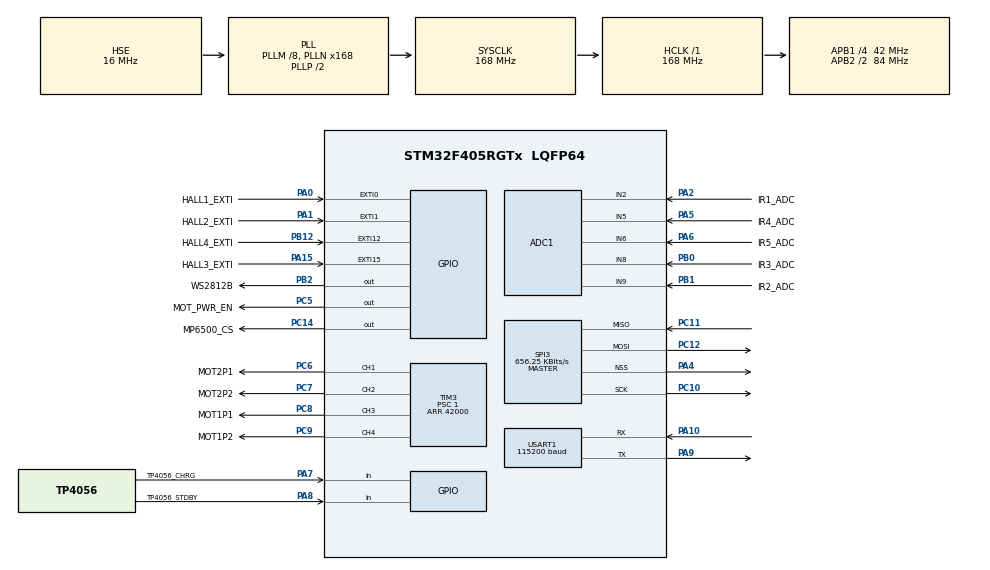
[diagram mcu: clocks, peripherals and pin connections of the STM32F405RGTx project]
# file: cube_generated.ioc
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ADC1.Channel-0\#ChannelRegularConversion=ADC_CHANNEL_2
ADC1.Channel-1\#ChannelRegularConversion=ADC_CHANNEL_5
ADC1.Channel-2\#ChannelRegularConversion=ADC_CHANNEL_6
ADC1.Channel-3\#ChannelRegularConversion=ADC_CHANNEL_8
ADC1.Channel-4\#ChannelRegularConversion=ADC_CHANNEL_9
ADC1.ClockPrescaler=ADC_CLOCK_SYNC_PCLK_DIV8
ADC1.ContinuousConvMode=DISABLE
ADC1.DMAContinuousRequests=ENABLE
ADC1.EOCSelection=ADC_EOC_SEQ_CONV
ADC1.ExternalTrigConv=ADC_EXTERNALTRIGCONV_T8_TRGO
ADC1.InjNumberOfConversion=0
ADC1.NbrOfConversion=5
ADC1.NbrOfConversionFlag=1
ADC1.Rank-0\#ChannelRegularConversion=1
ADC1.Rank-1\#ChannelRegularConversion=2
ADC1.Rank-2\#ChannelRegularConversion=3
ADC1.Rank-3\#ChannelRegularConversion=4
ADC1.Rank-4\#ChannelRegularConversion=5
ADC1.SamplingTime-0\#ChannelRegularConversion=ADC_SAMPLETIME_480CYCLES
ADC1.SamplingTime-1\#ChannelRegularConversion=ADC_SAMPLETIME_480CYCLES
ADC1.SamplingTime-2\#ChannelRegularConversion=ADC_SAMPLETIME_480CYCLES
ADC1.SamplingTime-3\#ChannelRegularConversion=ADC_SAMPLETIME_480CYCLES
ADC1.SamplingTime-4\#ChannelRegularConversion=ADC_SAMPLETIME_480CYCLES
ADC1.master=1
Dma.ADC1.4.Direction=DMA_PERIPH_TO_MEMORY
Dma.ADC1.4.FIFOMode=DMA_FIFOMODE_DISABLE
Dma.ADC1.4.Instance=DMA2_Stream0
Dma.ADC1.4.MemDataAlignment=DMA_MDATAALIGN_HALFWORD
Dma.ADC1.4.MemInc=DMA_MINC_ENABLE
Dma.ADC1.4.Mode=DMA_CIRCULAR
Dma.ADC1.4.PeriphDataAlignment=DMA_PDATAALIGN_HALFWORD
Dma.ADC1.4.PeriphInc=DMA_PINC_DISABLE
Dma.ADC1.4.Priority=DMA_PRIORITY_LOW
Dma.Request0=USART1_TX
Dma.Request1=USART1_RX
Dma.Request2=SPI3_RX
Dma.Request3=SPI3_TX
Dma.Request4=ADC1
Dma.SPI3_RX.2.Direction=DMA_PERIPH_TO_MEMORY
Dma.SPI3_RX.2.FIFOMode=DMA_FIFOMODE_DISABLE
Dma.SPI3_RX.2.Instance=DMA1_Stream0
Dma.SPI3_RX.2.MemDataAlignment=DMA_MDATAALIGN_BYTE
Dma.SPI3_RX.2.MemInc=DMA_MINC_ENABLE
Dma.SPI3_RX.2.Mode=DMA_NORMAL
Dma.SPI3_RX.2.PeriphDataAlignment=DMA_PDATAALIGN_BYTE
Dma.SPI3_RX.2.PeriphInc=DMA_PINC_DISABLE
Dma.SPI3_RX.2.Priority=DMA_PRIORITY_LOW
Dma.SPI3_TX.3.Direction=DMA_MEMORY_TO_PERIPH
Dma.SPI3_TX.3.FIFOMode=DMA_FIFOMODE_DISABLE
Dma.SPI3_TX.3.Instance=DMA1_Stream5
Dma.SPI3_TX.3.MemDataAlignment=DMA_MDATAALIGN_BYTE
Dma.SPI3_TX.3.MemInc=DMA_MINC_ENABLE
Dma.SPI3_TX.3.Mode=DMA_NORMAL
Dma.SPI3_TX.3.PeriphDataAlignment=DMA_PDATAALIGN_BYTE
Dma.SPI3_TX.3.PeriphInc=DMA_PINC_DISABLE
Dma.SPI3_TX.3.Priority=DMA_PRIORITY_LOW
Dma.USART1_RX.1.Direction=DMA_PERIPH_TO_MEMORY
Dma.USART1_RX.1.FIFOMode=DMA_FIFOMODE_DISABLE
Dma.USART1_RX.1.Instance=DMA2_Stream2
Dma.USART1_RX.1.MemDataAlignment=DMA_MDATAALIGN_BYTE
Dma.USART1_RX.1.MemInc=DMA_MINC_ENABLE
Dma.USART1_RX.1.Mode=DMA_NORMAL
Dma.USART1_RX.1.PeriphDataAlignment=DMA_PDATAALIGN_BYTE
Dma.USART1_RX.1.PeriphInc=DMA_PINC_DISABLE
Dma.USART1_RX.1.Priority=DMA_PRIORITY_LOW
Dma.USART1_TX.0.Direction=DMA_MEMORY_TO_PERIPH
Dma.USART1_TX.0.FIFOMode=DMA_FIFOMODE_DISABLE
Dma.USART1_TX.0.Instance=DMA2_Stream7
Dma.USART1_TX.0.MemDataAlignment=DMA_MDATAALIGN_BYTE
Dma.USART1_TX.0.MemInc=DMA_MINC_ENABLE
Dma.USART1_TX.0.Mode=DMA_NORMAL
Dma.USART1_TX.0.PeriphDataAlignment=DMA_PDATAALIGN_BYTE
Dma.USART1_TX.0.PeriphInc=DMA_PINC_DISABLE
Dma.USART1_TX.0.Priority=DMA_PRIORITY_LOW
Mcu.Family=STM32F4
Mcu.Name=STM32F405RGTx
Mcu.Package=LQFP64
NVIC.DMA1_Stream0_IRQn=true\:12\:0\:true\:false\:true\:false\:true\:true
NVIC.DMA1_Stream5_IRQn=true\:12\:0\:true\:false\:true\:false\:true\:true
NVIC.DMA2_Stream0_IRQn=true\:9\:0\:true\:false\:true\:false\:true\:true
NVIC.DMA2_Stream2_IRQn=true\:13\:0\:true\:false\:true\:false\:true\:true
NVIC.DMA2_Stream7_IRQn=true\:13\:0\:true\:false\:true\:false\:true\:true
NVIC.EXTI0_IRQn=true\:5\:0\:true\:false\:true\:true\:true\:true
NVIC.EXTI15_10_IRQn=true\:5\:0\:true\:false\:true\:true\:true\:true
NVIC.EXTI1_IRQn=true\:5\:0\:true\:false\:true\:true\:true\:true
NVIC.PriorityGroup=NVIC_PRIORITYGROUP_4
NVIC.TIM1_UP_TIM10_IRQn=true\:0\:0\:false\:false\:false\:true\:true\:true
NVIC.TIM2_IRQn=true\:0\:0\:false\:false\:true\:true\:true\:true
NVIC.TIM6_DAC_IRQn=true\:15\:0\:false\:false\:true\:false\:true\:true
NVIC.TIM8_TRG_COM_TIM14_IRQn=true\:5\:0\:true\:false\:true\:true\:true\:true
NVIC.TIM8_UP_TIM13_IRQn=true\:5\:0\:true\:false\:true\:true\:true\:true
NVIC.TimeBase=TIM6_DAC_IRQn
NVIC.TimeBaseIP=TIM6
NVIC.USART1_IRQn=true\:13\:0\:true\:false\:true\:true\:true\:true
PA0-WKUP.GPIO_Label=HALL1_EXTI
PA0-WKUP.GPIO_ModeDefaultEXTI=GPIO_MODE_IT_RISING_FALLING
PA0-WKUP.Signal=GPXTI0
PA1.GPIO_Label=HALL2_EXTI
PA1.GPIO_ModeDefaultEXTI=GPIO_MODE_IT_RISING_FALLING
PA1.Signal=GPXTI1
PA10.Mode=Asynchronous
PA10.Signal=USART1_RX
PA13.Mode=Trace_Asynchronous_SW
PA13.Signal=SYS_JTMS-SWDIO
PA14.Mode=Trace_Asynchronous_SW
PA14.Signal=SYS_JTCK-SWCLK
PA15.GPIO_Label=HALL3_EXTI
PA15.GPIO_ModeDefaultEXTI=GPIO_MODE_IT_RISING_FALLING
PA15.Signal=GPXTI15
PA2.GPIO_Label=IR1_ADC
PA2.Signal=ADCx_IN2
PA4.Mode=NSS_Signal_Hard_Output
PA4.Signal=SPI3_NSS
PA5.GPIO_Label=IR4_ADC
PA5.Signal=ADCx_IN5
PA6.GPIO_Label=IR5_ADC
PA6.Signal=ADCx_IN6
PA7.GPIO_Label=TP4056_CHRG
PA7.Signal=GPIO_Input
PA8.GPIO_Label=TP4056_STDBY
PA8.Signal=GPIO_Input
PA9.Mode=Asynchronous
PA9.Signal=USART1_TX
PB0.GPIO_Label=IR3_ADC
PB0.Signal=ADCx_IN8
PB1.GPIO_Label=IR2_ADC
PB1.Signal=ADCx_IN9
PB12.GPIO_Label=HALL4_EXTI
PB12.GPIO_ModeDefaultEXTI=GPIO_MODE_IT_RISING_FALLING
PB12.GPIO_PuPd=GPIO_PULLUP
PB12.Signal=GPXTI12
PB2.GPIO_Label=WS2812B
PB2.Signal=GPIO_Output
PB3.Mode=Trace_Asynchronous_SW
PB3.Signal=SYS_JTDO-SWO
PB8.Signal=S_TIM10_CH1
PC10.Mode=Full_Duplex_Master
PC10.Signal=SPI3_SCK
PC11.Mode=Full_Duplex_Master
PC11.Signal=SPI3_MISO
PC12.Mode=Full_Duplex_Master
PC12.Signal=SPI3_MOSI
PC14-OSC32_IN.GPIO_Label=MP6500_CS
PC14-OSC32_IN.Signal=GPIO_Output
PC5.GPIO_Label=MOT_PWR_EN
PC5.Signal=GPIO_Output
PC6.GPIO_Label=MOT2P1
PC6.Signal=S_TIM3_CH1
PC7.GPIO_Label=MOT2P2
PC7.Signal=S_TIM3_CH2
PC8.GPIO_Label=MOT1P1
PC8.Signal=S_TIM3_CH3
PC9.GPIO_Label=MOT1P2
PC9.Signal=S_TIM3_CH4
PH0-OSC_IN.Mode=HSE-External-Oscillator
PH0-OSC_IN.Signal=RCC_OSC_IN
PH1-OSC_OUT.Mode=HSE-External-Oscillator
PH1-OSC_OUT.Signal=RCC_OSC_OUT
ProjectManager.HeapSize=0x800
ProjectManager.StackSize=0x800
ProjectManager.TargetToolchain=Makefile
RCC.48MHZClocksFreq_Value=84000000
RCC.AHBFreq_Value=168000000
RCC.APB1CLKDivider=RCC_HCLK_DIV4
RCC.APB1Freq_Value=42000000
RCC.APB1TimFreq_Value=84000000
RCC.APB2CLKDivider=RCC_HCLK_DIV2
RCC.APB2Freq_Value=84000000
RCC.APB2TimFreq_Value=168000000
RCC.CortexFreq_Value=168000000
RCC.HCLKFreq_Value=168000000
RCC.HSE_VALUE=16000000
RCC.HSI_VALUE=16000000
RCC.LSE_VALUE=32768
RCC.PLLM=8
RCC.PLLN=168
RCC.PLLSourceVirtual=RCC_PLLSOURCE_HSE
RCC.SYSCLKFreq_VALUE=168000000
RCC.SYSCLKSource=RCC_SYSCLKSOURCE_PLLCLK
RCC.VCOOutputFreq_Value=336000000
SH.ADCx_IN2.0=ADC1_IN2,IN2
SH.ADCx_IN5.0=ADC1_IN5,IN5
SH.ADCx_IN6.0=ADC1_IN6,IN6
SH.ADCx_IN8.0=ADC1_IN8,IN8
SH.ADCx_IN9.0=ADC1_IN9,IN9
SH.S_TIM10_CH1.0=TIM10_CH1
SH.S_TIM3_CH1.0=TIM3_CH1,PWM Generation1 CH1
SH.S_TIM3_CH2.0=TIM3_CH2,PWM Generation2 CH2
SH.S_TIM3_CH3.0=TIM3_CH3,PWM Generation3 CH3
SH.S_TIM3_CH4.0=TIM3_CH4,PWM Generation4 CH4
SPI3.BaudRatePrescaler=SPI_BAUDRATEPRESCALER_64
SPI3.CalculateBaudRate=656.25 KBits/s
SPI3.Direction=SPI_DIRECTION_2LINES
SPI3.Mode=SPI_MODE_MASTER
SPI3.VirtualNSS=VM_NSSHARD
SPI3.VirtualType=VM_MASTER
TIM10.Channel=TIM_CHANNEL_1
TIM10.OCFastMode_PWM=TIM_OCFAST_ENABLE
TIM10.Period=104
TIM10.Prescaler=0
TIM10.Pulse=66
TIM2.Prescaler=83
TIM3.Channel-PWM\ Generation1\ CH1=TIM_CHANNEL_1
TIM3.Channel-PWM\ Generation2\ CH2=TIM_CHANNEL_2
TIM3.Channel-PWM\ Generation3\ CH3=TIM_CHANNEL_3
TIM3.Channel-PWM\ Generation4\ CH4=TIM_CHANNEL_4
TIM3.CounterMode=TIM_COUNTERMODE_CENTERALIGNED1
TIM3.Period=42000
TIM3.Prescaler=1
TIM3.Pulse-PWM\ Generation1\ CH1=40000
TIM3.Pulse-PWM\ Generation2\ CH2=2000
TIM3.Pulse-PWM\ Generation3\ CH3=10000
TIM3.Pulse-PWM\ Generation4\ CH4=30000
TIM8.AutoReloadPreload=TIM_AUTORELOAD_PRELOAD_ENABLE
TIM8.Period=999
TIM8.Prescaler=167
TIM8.TIM_MasterOutputTrigger=TIM_TRGO_UPDATE
USART1.BaudRate=115200
USART1.VirtualMode=VM_ASYNC
VP_SYS_VS_tim6.Mode=TIM6
VP_TIM10_VS_ClockSourceINT.Mode=Enable_Timer
VP_TIM10_VS_no_output1.Mode=PWM Generation1 No Output
VP_TIM2_VS_ClockSourceINT.Mode=Internal
VP_TIM3_VS_ClockSourceINT.Mode=Internal
VP_TIM8_VS_ClockSourceINT.Mode=Internal
board=custom

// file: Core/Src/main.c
/* USER CODE BEGIN Header */
/**
  ******************************************************************************
  * @file           : main.c
  * @brief          : Main program body
  ******************************************************************************
  * @attention
  *
  * Copyright (c) 2024 STMicroelectronics.
  * All rights reserved.
  *
  * This software is licensed under terms that can be found in the LICENSE file
  * in the root directory of this software component.
  * If no LICENSE file comes with this software, it is provided AS-IS.
  *
  ******************************************************************************
  */
/* USER CODE END Header */
#include "main.h"

/* USER CODE BEGIN Includes */
#include "system.h"
/* USER CODE END Includes */

ADC_HandleTypeDef hadc1;
DMA_HandleTypeDef hdma_adc1;

SPI_HandleTypeDef hspi3;
DMA_HandleTypeDef hdma_spi3_rx;
DMA_HandleTypeDef hdma_spi3_tx;

TIM_HandleTypeDef htim2;
TIM_HandleTypeDef htim3;
TIM_HandleTypeDef htim8;
TIM_HandleTypeDef htim10;

UART_HandleTypeDef huart1;
DMA_HandleTypeDef hdma_usart1_tx;
DMA_HandleTypeDef hdma_usart1_rx;

void SystemClock_Config(void);
static void MX_GPIO_Init(void);
static void MX_DMA_Init(void);
static void MX_USART1_UART_Init(void);
static void MX_ADC1_Init(void);
static void MX_SPI3_Init(void);
static void MX_TIM3_Init(void);
static void MX_TIM8_Init(void);
static void MX_TIM10_Init(void);
static void MX_TIM2_Init(void);

int main(void)
{

  /* MCU Configuration--------------------------------------------------------*/

  /* Reset of all peripherals, Initializes the Flash interface and the Systick. */
  HAL_Init();

  /* Configure the system clock */
  SystemClock_Config();

  /* Initialize all configured peripherals */
  MX_GPIO_Init();
  MX_DMA_Init();
  MX_USART1_UART_Init();
  MX_ADC1_Init();
  MX_SPI3_Init();
  MX_TIM3_Init();
  MX_TIM8_Init();
  MX_TIM10_Init();
  MX_TIM2_Init();
  /* USER CODE BEGIN 2 */
  sys_init();
  /* USER CODE END 2 */

  /* Infinite loop */
  while (1)
  {

  }
}

void SystemClock_Config(void)
{
  RCC_OscInitTypeDef RCC_OscInitStruct = {0};
  RCC_ClkInitTypeDef RCC_ClkInitStruct = {0};

  /** Configure the main internal regulator output voltage
  */
  __HAL_RCC_PWR_CLK_ENABLE();
  __HAL_PWR_VOLTAGESCALING_CONFIG(PWR_REGULATOR_VOLTAGE_SCALE1);

  /** Initializes the RCC Oscillators according to the specified parameters
  * in the RCC_OscInitTypeDef structure.
  */
  RCC_OscInitStruct.OscillatorType = RCC_OSCILLATORTYPE_HSE;
  RCC_OscInitStruct.HSEState = RCC_HSE_ON;
  RCC_OscInitStruct.PLL.PLLState = RCC_PLL_ON;
  RCC_OscInitStruct.PLL.PLLSource = RCC_PLLSOURCE_HSE;
  RCC_OscInitStruct.PLL.PLLM = 8;
  RCC_OscInitStruct.PLL.PLLN = 168;
  RCC_OscInitStruct.PLL.PLLP = RCC_PLLP_DIV2;
  RCC_OscInitStruct.PLL.PLLQ = 4;
  if (HAL_RCC_OscConfig(&RCC_OscInitStruct) != HAL_OK)
  {
    Error_Handler();
  }

  /** Initializes the CPU, AHB and APB buses clocks
  */
  RCC_ClkInitStruct.ClockType = RCC_CLOCKTYPE_HCLK|RCC_CLOCKTYPE_SYSCLK
                              |RCC_CLOCKTYPE_PCLK1|RCC_CLOCKTYPE_PCLK2;
  RCC_ClkInitStruct.SYSCLKSource = RCC_SYSCLKSOURCE_PLLCLK;
  RCC_ClkInitStruct.AHBCLKDivider = RCC_SYSCLK_DIV1;
  RCC_ClkInitStruct.APB1CLKDivider = RCC_HCLK_DIV4;
  RCC_ClkInitStruct.APB2CLKDivider = RCC_HCLK_DIV2;

  if (HAL_RCC_ClockConfig(&RCC_ClkInitStruct, FLASH_LATENCY_5) != HAL_OK)
  {
    Error_Handler();
  }
}

static void MX_ADC1_Init(void)
{

  ADC_ChannelConfTypeDef sConfig = {0};

  /** Configure the global features of the ADC (Clock, Resolution, Data Alignment and number of conversion)
  */
  hadc1.Instance = ADC1;
  hadc1.Init.ClockPrescaler = ADC_CLOCK_SYNC_PCLK_DIV8;
  hadc1.Init.Resolution = ADC_RESOLUTION_12B;
  hadc1.Init.ScanConvMode = ENABLE;
  hadc1.Init.ContinuousConvMode = DISABLE;
  hadc1.Init.DiscontinuousConvMode = DISABLE;
  hadc1.Init.ExternalTrigConvEdge = ADC_EXTERNALTRIGCONVEDGE_RISING;
  hadc1.Init.ExternalTrigConv = ADC_EXTERNALTRIGCONV_T8_TRGO;
  hadc1.Init.DataAlign = ADC_DATAALIGN_RIGHT;
  hadc1.Init.NbrOfConversion = 5;
  hadc1.Init.DMAContinuousRequests = ENABLE;
  hadc1.Init.EOCSelection = ADC_EOC_SEQ_CONV;
  if (HAL_ADC_Init(&hadc1) != HAL_OK)
  {
    Error_Handler();
  }

  /** Configure for the selected ADC regular channel its corresponding rank in the sequencer and its sample time.
  */
  sConfig.Channel = ADC_CHANNEL_2;
  sConfig.Rank = 1;
  sConfig.SamplingTime = ADC_SAMPLETIME_480CYCLES;
  if (HAL_ADC_ConfigChannel(&hadc1, &sConfig) != HAL_OK)
  {
    Error_Handler();
  }

  /** Configure for the selected ADC regular channel its corresponding rank in the sequencer and its sample time.
  */
  sConfig.Channel = ADC_CHANNEL_5;
  sConfig.Rank = 2;
  if (HAL_ADC_ConfigChannel(&hadc1, &sConfig) != HAL_OK)
  {
    Error_Handler();
  }

  /** Configure for the selected ADC regular channel its corresponding rank in the sequencer and its sample time.
  */
  sConfig.Channel = ADC_CHANNEL_6;
  sConfig.Rank = 3;
  if (HAL_ADC_ConfigChannel(&hadc1, &sConfig) != HAL_OK)
  {
    Error_Handler();
  }

  /** Configure for the selected ADC regular channel its corresponding rank in the sequencer and its sample time.
  */
  sConfig.Channel = ADC_CHANNEL_8;
  sConfig.Rank = 4;
  if (HAL_ADC_ConfigChannel(&hadc1, &sConfig) != HAL_OK)
  {
    Error_Handler();
  }

  /** Configure for the selected ADC regular channel its corresponding rank in the sequencer and its sample time.
  */
  sConfig.Channel = ADC_CHANNEL_9;
  sConfig.Rank = 5;
  if (HAL_ADC_ConfigChannel(&hadc1, &sConfig) != HAL_OK)
  {
    Error_Handler();
  }

}

static void MX_SPI3_Init(void)
{

  /* SPI3 parameter configuration*/
  hspi3.Instance = SPI3;
  hspi3.Init.Mode = SPI_MODE_MASTER;
  hspi3.Init.Direction = SPI_DIRECTION_2LINES;
  hspi3.Init.DataSize = SPI_DATASIZE_8BIT;
  hspi3.Init.CLKPolarity = SPI_POLARITY_LOW;
  hspi3.Init.CLKPhase = SPI_PHASE_1EDGE;
  hspi3.Init.NSS = SPI_NSS_HARD_OUTPUT;
  hspi3.Init.BaudRatePrescaler = SPI_BAUDRATEPRESCALER_64;
  hspi3.Init.FirstBit = SPI_FIRSTBIT_MSB;
  hspi3.Init.TIMode = SPI_TIMODE_DISABLE;
  hspi3.Init.CRCCalculation = SPI_CRCCALCULATION_DISABLE;
  hspi3.Init.CRCPolynomial = 10;
  if (HAL_SPI_Init(&hspi3) != HAL_OK)
  {
    Error_Handler();
  }

}

static void MX_TIM2_Init(void)
{

  TIM_ClockConfigTypeDef sClockSourceConfig = {0};
  TIM_MasterConfigTypeDef sMasterConfig = {0};

  htim2.Instance = TIM2;
  htim2.Init.Prescaler = 83;
  htim2.Init.CounterMode = TIM_COUNTERMODE_UP;
  htim2.Init.Period = 4294967295;
  htim2.Init.ClockDivision = TIM_CLOCKDIVISION_DIV1;
  htim2.Init.AutoReloadPreload = TIM_AUTORELOAD_PRELOAD_DISABLE;
  if (HAL_TIM_Base_Init(&htim2) != HAL_OK)
  {
    Error_Handler();
  }
  sClockSourceConfig.ClockSource = TIM_CLOCKSOURCE_INTERNAL;
  if (HAL_TIM_ConfigClockSource(&htim2, &sClockSourceConfig) != HAL_OK)
  {
    Error_Handler();
  }
  sMasterConfig.MasterOutputTrigger = TIM_TRGO_RESET;
  sMasterConfig.MasterSlaveMode = TIM_MASTERSLAVEMODE_DISABLE;
  if (HAL_TIMEx_MasterConfigSynchronization(&htim2, &sMasterConfig) != HAL_OK)
  {
    Error_Handler();
  }

}

static void MX_TIM3_Init(void)
{

  TIM_ClockConfigTypeDef sClockSourceConfig = {0};
  TIM_MasterConfigTypeDef sMasterConfig = {0};
  TIM_OC_InitTypeDef sConfigOC = {0};

  htim3.Instance = TIM3;
  htim3.Init.Prescaler = 1;
  htim3.Init.CounterMode = TIM_COUNTERMODE_CENTERALIGNED1;
  htim3.Init.Period = 42000;
  htim3.Init.ClockDivision = TIM_CLOCKDIVISION_DIV1;
  htim3.Init.AutoReloadPreload = TIM_AUTORELOAD_PRELOAD_DISABLE;
  if (HAL_TIM_Base_Init(&htim3) != HAL_OK)
  {
    Error_Handler();
  }
  sClockSourceConfig.ClockSource = TIM_CLOCKSOURCE_INTERNAL;
  if (HAL_TIM_ConfigClockSource(&htim3, &sClockSourceConfig) != HAL_OK)
  {
    Error_Handler();
  }
  if (HAL_TIM_PWM_Init(&htim3) != HAL_OK)
  {
    Error_Handler();
  }
  sMasterConfig.MasterOutputTrigger = TIM_TRGO_RESET;
  sMasterConfig.MasterSlaveMode = TIM_MASTERSLAVEMODE_DISABLE;
  if (HAL_TIMEx_MasterConfigSynchronization(&htim3, &sMasterConfig) != HAL_OK)
  {
    Error_Handler();
  }
  sConfigOC.OCMode = TIM_OCMODE_PWM1;
  sConfigOC.Pulse = 40000;
  sConfigOC.OCPolarity = TIM_OCPOLARITY_HIGH;
  sConfigOC.OCFastMode = TIM_OCFAST_DISABLE;
  if (HAL_TIM_PWM_ConfigChannel(&htim3, &sConfigOC, TIM_CHANNEL_1) != HAL_OK)
  {
    Error_Handler();
  }
  sConfigOC.Pulse = 2000;
  if (HAL_TIM_PWM_ConfigChannel(&htim3, &sConfigOC, TIM_CHANNEL_2) != HAL_OK)
  {
    Error_Handler();
  }
  sConfigOC.Pulse = 10000;
  if (HAL_TIM_PWM_ConfigChannel(&htim3, &sConfigOC, TIM_CHANNEL_3) != HAL_OK)
  {
    Error_Handler();
  }
  sConfigOC.Pulse = 30000;
  if (HAL_TIM_PWM_ConfigChannel(&htim3, &sConfigOC, TIM_CHANNEL_4) != HAL_OK)
  {
    Error_Handler();
  }
  HAL_TIM_MspPostInit(&htim3);

}

static void MX_TIM8_Init(void)
{

  TIM_ClockConfigTypeDef sClockSourceConfig = {0};
  TIM_MasterConfigTypeDef sMasterConfig = {0};

  htim8.Instance = TIM8;
  htim8.Init.Prescaler = 167;
  htim8.Init.CounterMode = TIM_COUNTERMODE_UP;
  htim8.Init.Period = 999;
  htim8.Init.ClockDivision = TIM_CLOCKDIVISION_DIV1;
  htim8.Init.RepetitionCounter = 0;
  htim8.Init.AutoReloadPreload = TIM_AUTORELOAD_PRELOAD_ENABLE;
  if (HAL_TIM_Base_Init(&htim8) != HAL_OK)
  {
    Error_Handler();
  }
  sClockSourceConfig.ClockSource = TIM_CLOCKSOURCE_INTERNAL;
  if (HAL_TIM_ConfigClockSource(&htim8, &sClockSourceConfig) != HAL_OK)
  {
    Error_Handler();
  }
  sMasterConfig.MasterOutputTrigger = TIM_TRGO_UPDATE;
  sMasterConfig.MasterSlaveMode = TIM_MASTERSLAVEMODE_DISABLE;
  if (HAL_TIMEx_MasterConfigSynchronization(&htim8, &sMasterConfig) != HAL_OK)
  {
    Error_Handler();
  }

}

static void MX_TIM10_Init(void)
{

  TIM_OC_InitTypeDef sConfigOC = {0};

  htim10.Instance = TIM10;
  htim10.Init.Prescaler = 0;
  htim10.Init.CounterMode = TIM_COUNTERMODE_UP;
  htim10.Init.Period = 104;
  htim10.Init.ClockDivision = TIM_CLOCKDIVISION_DIV1;
  htim10.Init.AutoReloadPreload = TIM_AUTORELOAD_PRELOAD_DISABLE;
  if (HAL_TIM_Base_Init(&htim10) != HAL_OK)
  {
    Error_Handler();
  }
  if (HAL_TIM_PWM_Init(&htim10) != HAL_OK)
  {
    Error_Handler();
  }
  sConfigOC.OCMode = TIM_OCMODE_PWM1;
  sConfigOC.Pulse = 66;
  sConfigOC.OCPolarity = TIM_OCPOLARITY_HIGH;
  sConfigOC.OCFastMode = TIM_OCFAST_ENABLE;
  if (HAL_TIM_PWM_ConfigChannel(&htim10, &sConfigOC, TIM_CHANNEL_1) != HAL_OK)
  {
    Error_Handler();
  }

}

static void MX_USART1_UART_Init(void)
{

  huart1.Instance = USART1;
  huart1.Init.BaudRate = 115200;
  huart1.Init.WordLength = UART_WORDLENGTH_8B;
  huart1.Init.StopBits = UART_STOPBITS_1;
  huart1.Init.Parity = UART_PARITY_NONE;
  huart1.Init.Mode = UART_MODE_TX_RX;
  huart1.Init.HwFlowCtl = UART_HWCONTROL_NONE;
  huart1.Init.OverSampling = UART_OVERSAMPLING_16;
  if (HAL_UART_Init(&huart1) != HAL_OK)
  {
    Error_Handler();
  }

}

static void MX_DMA_Init(void)
{

  /* DMA controller clock enable */
  __HAL_RCC_DMA2_CLK_ENABLE();
  __HAL_RCC_DMA1_CLK_ENABLE();

  /* DMA interrupt init */
  /* DMA1_Stream0_IRQn interrupt configuration */
  HAL_NVIC_SetPriority(DMA1_Stream0_IRQn, 12, 0);
  HAL_NVIC_EnableIRQ(DMA1_Stream0_IRQn);
  /* DMA1_Stream5_IRQn interrupt configuration */
  HAL_NVIC_SetPriority(DMA1_Stream5_IRQn, 12, 0);
  HAL_NVIC_EnableIRQ(DMA1_Stream5_IRQn);
  /* DMA2_Stream0_IRQn interrupt configuration */
  HAL_NVIC_SetPriority(DMA2_Stream0_IRQn, 9, 0);
  HAL_NVIC_EnableIRQ(DMA2_Stream0_IRQn);
  /* DMA2_Stream2_IRQn interrupt configuration */
  HAL_NVIC_SetPriority(DMA2_Stream2_IRQn, 13, 0);
  HAL_NVIC_EnableIRQ(DMA2_Stream2_IRQn);
  /* DMA2_Stream7_IRQn interrupt configuration */
  HAL_NVIC_SetPriority(DMA2_Stream7_IRQn, 13, 0);
  HAL_NVIC_EnableIRQ(DMA2_Stream7_IRQn);

}

static void MX_GPIO_Init(void)
{
  GPIO_InitTypeDef GPIO_InitStruct = {0};

  /* GPIO Ports Clock Enable */
  __HAL_RCC_GPIOC_CLK_ENABLE();
  __HAL_RCC_GPIOH_CLK_ENABLE();
  __HAL_RCC_GPIOA_CLK_ENABLE();
  __HAL_RCC_GPIOB_CLK_ENABLE();

  /*Configure GPIO pin Output Level */
  HAL_GPIO_WritePin(GPIOC, MP6500_CS_Pin|MOT_PWR_EN_Pin, GPIO_PIN_RESET);

  /*Configure GPIO pin Output Level */
  HAL_GPIO_WritePin(WS2812B_GPIO_Port, WS2812B_Pin, GPIO_PIN_RESET);

  /*Configure GPIO pins : MP6500_CS_Pin MOT_PWR_EN_Pin */
  GPIO_InitStruct.Pin = MP6500_CS_Pin|MOT_PWR_EN_Pin;
  GPIO_InitStruct.Mode = GPIO_MODE_OUTPUT_PP;
  GPIO_InitStruct.Pull = GPIO_NOPULL;
  GPIO_InitStruct.Speed = GPIO_SPEED_FREQ_LOW;
  HAL_GPIO_Init(GPIOC, &GPIO_InitStruct);

  /*Configure GPIO pins : HALL1_EXTI_Pin HALL2_EXTI_Pin HALL3_EXTI_Pin */
  GPIO_InitStruct.Pin = HALL1_EXTI_Pin|HALL2_EXTI_Pin|HALL3_EXTI_Pin;
  GPIO_InitStruct.Mode = GPIO_MODE_IT_RISING_FALLING;
  GPIO_InitStruct.Pull = GPIO_NOPULL;
  HAL_GPIO_Init(GPIOA, &GPIO_InitStruct);

  /*Configure GPIO pins : TP4056_CHRG_Pin TP4056_STDBY_Pin */
  GPIO_InitStruct.Pin = TP4056_CHRG_Pin|TP4056_STDBY_Pin;
  GPIO_InitStruct.Mode = GPIO_MODE_INPUT;
  GPIO_InitStruct.Pull = GPIO_NOPULL;
  HAL_GPIO_Init(GPIOA, &GPIO_InitStruct);

  /*Configure GPIO pin : WS2812B_Pin */
  GPIO_InitStruct.Pin = WS2812B_Pin;
  GPIO_InitStruct.Mode = GPIO_MODE_OUTPUT_PP;
  GPIO_InitStruct.Pull = GPIO_NOPULL;
  GPIO_InitStruct.Speed = GPIO_SPEED_FREQ_LOW;
  HAL_GPIO_Init(WS2812B_GPIO_Port, &GPIO_InitStruct);

  /*Configure GPIO pin : HALL4_EXTI_Pin */
  GPIO_InitStruct.Pin = HALL4_EXTI_Pin;
  GPIO_InitStruct.Mode = GPIO_MODE_IT_RISING_FALLING;
  GPIO_InitStruct.Pull = GPIO_PULLUP;
  HAL_GPIO_Init(HALL4_EXTI_GPIO_Port, &GPIO_InitStruct);

  /* EXTI interrupt init*/
  HAL_NVIC_SetPriority(EXTI0_IRQn, 5, 0);
  HAL_NVIC_EnableIRQ(EXTI0_IRQn);

  HAL_NVIC_SetPriority(EXTI1_IRQn, 5, 0);
  HAL_NVIC_EnableIRQ(EXTI1_IRQn);

  HAL_NVIC_SetPriority(EXTI15_10_IRQn, 5, 0);
  HAL_NVIC_EnableIRQ(EXTI15_10_IRQn);

}

void HAL_TIM_PeriodElapsedCallback(TIM_HandleTypeDef *htim)
{
  if (htim->Instance == TIM6) {
    HAL_IncTick();
  }
}

void Error_Handler(void)
{
  __disable_irq();
  while (1)
  {
  }
}
